AUTOSAR XML (schema 4-2-2)
package /ASW_COM_STD_Pkg
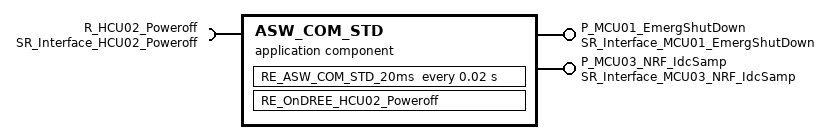
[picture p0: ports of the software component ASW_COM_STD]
  application sw component type ASW_COM_STD
    provide port P_MCU01_EmergShutDown: non-queued-sender-com-spec{data-element=DE_EmergShutDown, init-value=constant-reference=label=INIT_VALUE_EmergShutDown}, provided-interface=SR_Interface_MCU01_EmergShutDown
    provide port P_MCU03_NRF_IdcSamp: non-queued-sender-com-spec{data-element=DE_NRF_IdcSamp, init-value=constant-reference=label=INIT_VALUE_NRF_IdcSamp}, provided-interface=SR_Interface_MCU03_NRF_IdcSamp
    require port R_HCU02_Poweroff: non-queued-receiver-com-spec{data-element=DE_Poweroff, uses-end-to-end-protection=false, alive-timeout=0.3, init-value=constant-reference=label=INIT_VALUE_Poweroff}, required-interface=SR_Interface_HCU02_Poweroff
    behavior IB_ASW_COM_STD
      timing event TE_ASW_COM_STD_20ms: start-on-event=RE_ASW_COM_STD_20ms, period=0.02
      data receive error event DREE_HCU02_Poweroff: start-on-event=RE_OnDREE_HCU02_Poweroff, data=R_HCU02_Poweroff.DE_Poweroff
      runnable RE_ASW_COM_STD_20ms
        data-read-accesses:
          access RA_HCU02_Poweroff: accessed-variable=R_HCU02_Poweroff.DE_Poweroff
        data-write-accesses:
          access WA_MCU01_EmergShutDown: accessed-variable=P_MCU01_EmergShutDown.DE_EmergShutDown
          access WA_MCU03_NRF_IdcSamp: accessed-variable=P_MCU03_NRF_IdcSamp.DE_NRF_IdcSamp
      runnable RE_OnDREE_HCU02_Poweroff
